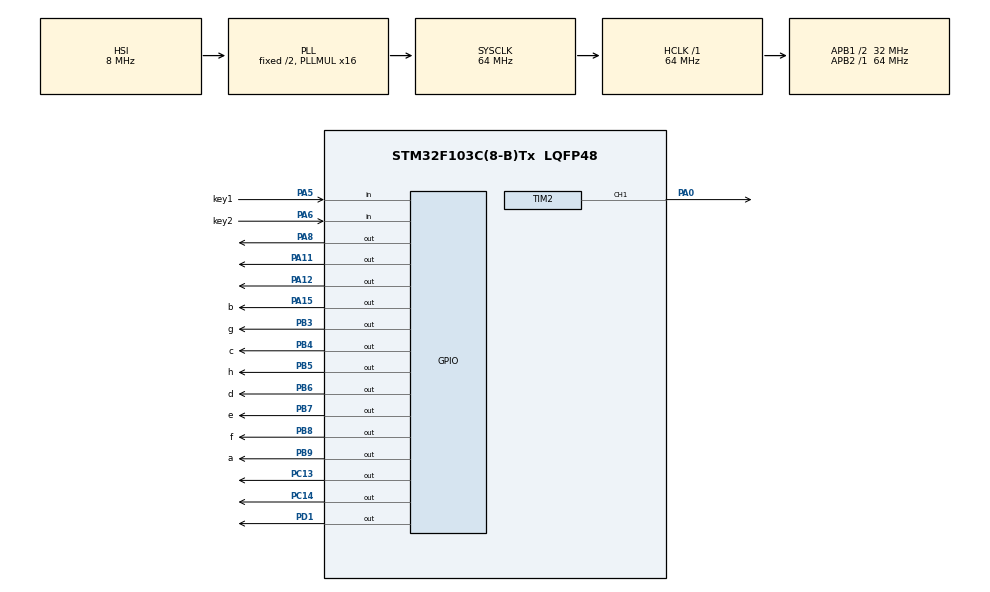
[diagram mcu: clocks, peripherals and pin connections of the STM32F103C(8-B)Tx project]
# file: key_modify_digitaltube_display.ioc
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Mcu.Family=STM32F1
Mcu.Name=STM32F103C(8-B)Tx
Mcu.Package=LQFP48
NVIC.PriorityGroup=NVIC_PRIORITYGROUP_4
PA0-WKUP.Signal=S_TIM2_CH1_ETR
PA11.Signal=GPIO_Output
PA12.Signal=GPIO_Output
PA13.Mode=Serial_Wire
PA13.Signal=SYS_JTMS-SWDIO
PA14.Mode=Serial_Wire
PA14.Signal=SYS_JTCK-SWCLK
PA15.GPIO_Label=b
PA15.Signal=GPIO_Output
PA5.GPIO_Label=key1
PA5.Signal=GPIO_Input
PA6.GPIO_Label=key2
PA6.Signal=GPIO_Input
PA8.Signal=GPIO_Output
PB3.GPIO_Label=g
PB3.Signal=GPIO_Output
PB4.GPIO_Label=c
PB4.Signal=GPIO_Output
PB5.GPIO_Label=h
PB5.Signal=GPIO_Output
PB6.GPIO_Label=d
PB6.Signal=GPIO_Output
PB7.GPIO_Label=e
PB7.Signal=GPIO_Output
PB8.GPIO_Label=f
PB8.Signal=GPIO_Output
PB9.GPIO_Label=a
PB9.Signal=GPIO_Output
PC13-TAMPER-RTC.Signal=GPIO_Output
PC14-OSC32_IN.Signal=GPIO_Output
PD1-OSC_OUT.Signal=GPIO_Output
ProjectManager.HeapSize=0x200
ProjectManager.StackSize=0x400
ProjectManager.TargetToolchain=MDK-ARM V5.32
RCC.AHBFreq_Value=64000000
RCC.APB1CLKDivider=RCC_HCLK_DIV2
RCC.APB1Freq_Value=32000000
RCC.APB1TimFreq_Value=64000000
RCC.APB2Freq_Value=64000000
RCC.APB2TimFreq_Value=64000000
RCC.HCLKFreq_Value=64000000
RCC.PLLMUL=RCC_PLL_MUL16
RCC.SYSCLKFreq_VALUE=64000000
RCC.SYSCLKSource=RCC_SYSCLKSOURCE_PLLCLK
RCC.USBFreq_Value=64000000
SH.S_TIM2_CH1_ETR.0=TIM2_CH1,PWM Generation1 CH1
TIM2.AutoReloadPreload=TIM_AUTORELOAD_PRELOAD_ENABLE
TIM2.Channel-PWM\ Generation1\ CH1=TIM_CHANNEL_1
TIM2.Period=999
TIM2.Prescaler=63
TIM2.Pulse-PWM\ Generation1\ CH1=500
VP_TIM2_VS_ClockSourceINT.Mode=Internal
board=custom

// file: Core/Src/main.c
/* USER CODE BEGIN Header */
/**
 ******************************************************************************
 * @file           : main.c
 * @brief          : Main program body
 ******************************************************************************
 * @attention
 *
 * Copyright (c) 2024 STMicroelectronics.
 * All rights reserved.
 *
 * This software is licensed under terms that can be found in the LICENSE file
 * in the root directory of this software component.
 * If no LICENSE file comes with this software, it is provided AS-IS.
 *
 ******************************************************************************
 */
/* USER CODE END Header */
#include "main.h"
#include "tim.h"
#include "gpio.h"

/* USER CODE BEGIN Includes */
// #include "seg_display.h"
// #include "my_key.h"
#include "my_app.h"

/* USER CODE END Includes */

void SystemClock_Config(void);

int main(void)
{

  /* MCU Configuration--------------------------------------------------------*/

  /* Reset of all peripherals, Initializes the Flash interface and the Systick. */
  HAL_Init();

  /* Configure the system clock */
  SystemClock_Config();

  /* Initialize all configured peripherals */
  MX_GPIO_Init();
  MX_TIM2_Init();
  /* USER CODE BEGIN 2 */
	user_pwm_init();
	user_duty_cycle_set(80);
  seg_setDisplayNum(2,4,6,8);
  /* USER CODE END 2 */

  /* Infinite loop */
  /* USER CODE BEGIN WHILE */
	while (1) {
    MyApp_Run();
    HAL_Delay(10);
    /* USER CODE END WHILE */

	// key_main();
	}
}

void SystemClock_Config(void)
{
  RCC_OscInitTypeDef RCC_OscInitStruct = {0};
  RCC_ClkInitTypeDef RCC_ClkInitStruct = {0};

  /** Initializes the RCC Oscillators according to the specified parameters
  * in the RCC_OscInitTypeDef structure.
  */
  RCC_OscInitStruct.OscillatorType = RCC_OSCILLATORTYPE_HSI;
  RCC_OscInitStruct.HSIState = RCC_HSI_ON;
  RCC_OscInitStruct.HSICalibrationValue = RCC_HSICALIBRATION_DEFAULT;
  RCC_OscInitStruct.PLL.PLLState = RCC_PLL_ON;
  RCC_OscInitStruct.PLL.PLLSource = RCC_PLLSOURCE_HSI_DIV2;
  RCC_OscInitStruct.PLL.PLLMUL = RCC_PLL_MUL16;
  if (HAL_RCC_OscConfig(&RCC_OscInitStruct) != HAL_OK)
  {
    Error_Handler();
  }

  /** Initializes the CPU, AHB and APB buses clocks
  */
  RCC_ClkInitStruct.ClockType = RCC_CLOCKTYPE_HCLK|RCC_CLOCKTYPE_SYSCLK
                              |RCC_CLOCKTYPE_PCLK1|RCC_CLOCKTYPE_PCLK2;
  RCC_ClkInitStruct.SYSCLKSource = RCC_SYSCLKSOURCE_PLLCLK;
  RCC_ClkInitStruct.AHBCLKDivider = RCC_SYSCLK_DIV1;
  RCC_ClkInitStruct.APB1CLKDivider = RCC_HCLK_DIV2;
  RCC_ClkInitStruct.APB2CLKDivider = RCC_HCLK_DIV1;

  if (HAL_RCC_ClockConfig(&RCC_ClkInitStruct, FLASH_LATENCY_2) != HAL_OK)
  {
    Error_Handler();
  }
}

void Error_Handler(void)
{
	__disable_irq();
	while (1) {
	}
}
